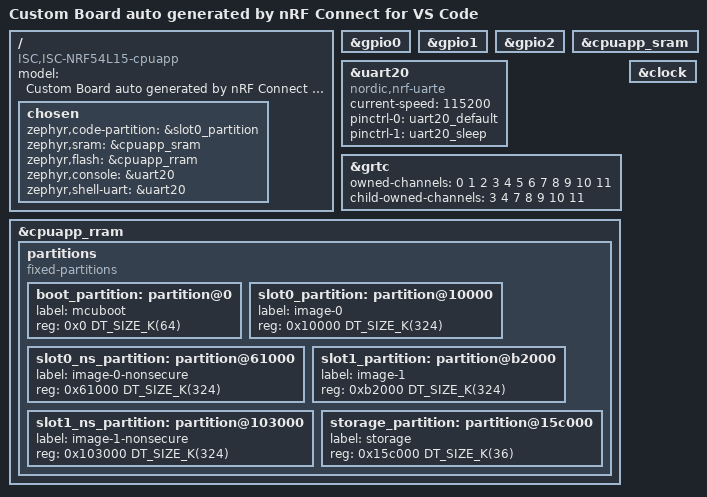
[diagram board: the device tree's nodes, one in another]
/dts-v1/;
#include <nordic/nrf54l15_cpuapp.dtsi>
#include "ISC_NRF54L15-pinctrl.dtsi"

/ {
	model = "Custom Board auto generated by nRF Connect for VS Code";
	compatible = "ISC,ISC-NRF54L15-cpuapp";

	chosen {
		zephyr,code-partition = &slot0_partition;
		zephyr,sram = &cpuapp_sram;
		zephyr,flash = &cpuapp_rram;
		zephyr,console = &uart20;       // added
        zephyr,shell-uart = &uart20;    // added
	};
};

&gpio0 {
    status = "okay";
};

&gpio1 {
    status = "okay";
};

&gpio2 {
    status = "okay";
};


&uart20 {
    compatible = "nordic,nrf-uarte";
    status = "okay";
    current-speed = <115200>;
    pinctrl-0 = <&uart20_default>;
    pinctrl-1 = <&uart20_sleep>;
    pinctrl-names = "default", "sleep";
};

&cpuapp_sram {
	status = "okay";
};

&grtc {
	owned-channels = <0 1 2 3 4 5 6 7 8 9 10 11>;
	/* Channels 7-11 reserved for Zero Latency IRQs, 3-4 for FLPR */
	child-owned-channels = <3 4 7 8 9 10 11>;
	status = "okay";
};

&cpuapp_rram {
	partitions {
		compatible = "fixed-partitions";
		#address-cells = <1>;
		#size-cells = <1>;
		boot_partition: partition@0 {
			label = "mcuboot";
			reg = <0x0 DT_SIZE_K(64)>;
		};
		slot0_partition: partition@10000 {
			label = "image-0";
			reg = <0x10000 DT_SIZE_K(324)>;
		};
		slot0_ns_partition: partition@61000 {
			label = "image-0-nonsecure";
			reg = <0x61000 DT_SIZE_K(324)>;
		};
		slot1_partition: partition@b2000 {
			label = "image-1";
			reg = <0xb2000 DT_SIZE_K(324)>;
		};
		slot1_ns_partition: partition@103000 {
			label = "image-1-nonsecure";
			reg = <0x103000 DT_SIZE_K(324)>;
		};
		/* 32k from 0x154000 to 0x15bfff reserved for TF-M partitions */
		storage_partition: partition@15c000 {
			label = "storage";
			reg = <0x15c000 DT_SIZE_K(36)>;
		};
	};
};

// &lfxo {
//     status = "okay";
//     load-capacitors = "internal";
//     load-capacitance-femtofarad = <15500>;
// };

&clock {
    status = "okay";
};


// &hfxo {
//     status = "okay";
//     load-capacitors = "internal";
//     load-capacitance-femtofarad = <15500>;
// };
